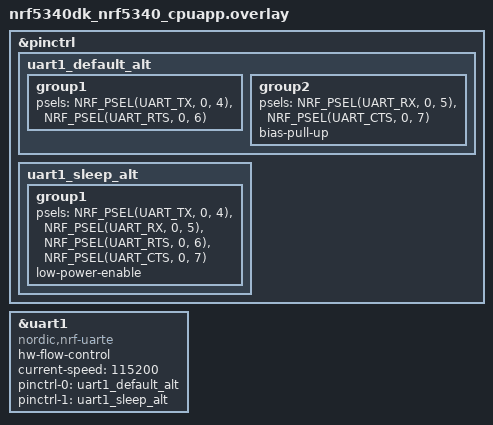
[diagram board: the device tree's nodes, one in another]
/* SPDX-License-Identifier: Apache-2.0 */

/*
 * Pins P0.4 and P0.5 must be connected to each other to loopback RX/TX.
 * For hw-flow-control, P0.6 and P0.7 must be connected to each other to enable RTS/CTS.
 */

&pinctrl {
	uart1_default_alt: uart1_default_alt {
		group1 {
			psels = <NRF_PSEL(UART_TX, 0, 4)>,
				<NRF_PSEL(UART_RTS, 0, 6)>;
		};
		group2 {
			psels = <NRF_PSEL(UART_RX, 0, 5)>,
				<NRF_PSEL(UART_CTS, 0, 7)>;
			bias-pull-up;
		};
	};

	uart1_sleep_alt: uart1_sleep_alt {
		group1 {
			psels = <NRF_PSEL(UART_TX, 0, 4)>,
				<NRF_PSEL(UART_RX, 0, 5)>,
				<NRF_PSEL(UART_RTS, 0, 6)>,
				<NRF_PSEL(UART_CTS, 0, 7)>;
			low-power-enable;
		};
	};
};

dut: &uart1 {
	compatible = "nordic,nrf-uarte";
	hw-flow-control;
	current-speed = <115200>;
	status = "okay";
	pinctrl-0 = <&uart1_default_alt>;
	pinctrl-1 = <&uart1_sleep_alt>;
	pinctrl-names = "default", "sleep";
};
